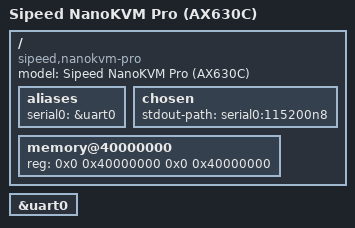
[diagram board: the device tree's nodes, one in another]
// SPDX-License-Identifier: GPL-2.0-or-later
/*
 * NanoKVM Pro (AX630C)
 */

/dts-v1/;

#include "ax620e.dtsi"

/ {
	model = "Sipeed NanoKVM Pro (AX630C)";
	compatible = "sipeed,nanokvm-pro", "axera,ax630c", "axera,ax620e";

	aliases {
		serial0 = &uart0;
	};

	chosen {
		stdout-path = "serial0:115200n8";
	};

	memory@40000000 {
		device_type = "memory";
		reg = <0x0 0x40000000 0x0 0x40000000>;
	};
};

&uart0 {
	status = "okay";
};
